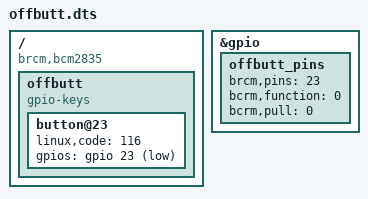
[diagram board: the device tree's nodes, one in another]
/dts-v1/;
/plugin/;
/ {
  compatible = "brcm,bcm2835", "brcm,bcm2708", "brcm,bcm2709";
  
  fragment@0 {
     target-path = "/";
     __overlay__ {
        offbutt: offbutt {
           compatible = "gpio-keys";
           button@23 {
              linux,code = <116>;
              gpios = <&gpio 23 1>;
           };

        };
     };
  };

  fragment@1 {
    target = <&gpio>;
    __overlay__ {
      offbutt_pins: offbutt_pins {
        brcm,pins = <23>;
        bcrm,function = <0>; //in
        bcrm,pull = <0>; //pull-up
      };
    };
  };

  __overrides__ {
    gpiopin    = <&offbutt>,"gpios:4",
                 <&offbutt_pins>,"bcrm,pins:0";
    active_low = <&offbutt_pins>,"bcrm,pull:0";
  };

};
